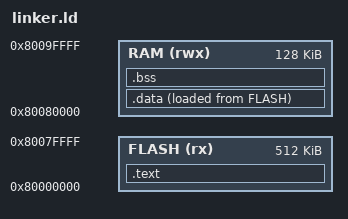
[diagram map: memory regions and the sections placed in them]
ENTRY(_start)

MEMORY
{
    FLASH (rx)  : ORIGIN = 0x80000000, LENGTH = 512K
    RAM   (rwx) : ORIGIN = 0x80080000, LENGTH = 128K
}

SECTIONS
{
    .text :
    {
        . = ALIGN(4);
        KEEP(*(.init))
        *(.text*)
        *(.rodata*)
        *(.srodata*)
        . = ALIGN(4);
    } > FLASH

    .data :
    {
        . = ALIGN(4);
        __data_start = .;
        *(.data*)
        *(.sdata*)
        . = ALIGN(4);
        __data_end = .;
    } > RAM AT > FLASH

    __data_load = LOADADDR(.data);

    .bss :
    {
        . = ALIGN(4);
        __bss_start = .;
        *(.bss*)
        *(.sbss*)
        *(COMMON)
        . = ALIGN(4);
        __bss_end = .;
    } > RAM

    . = ALIGN(16);
    _stack_top = ORIGIN(RAM) + LENGTH(RAM);
}
